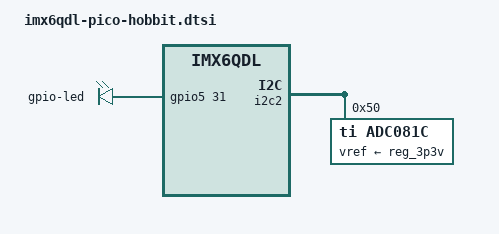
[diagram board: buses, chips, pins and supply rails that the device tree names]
// SPDX-License-Identifier: GPL-2.0+ OR MIT
//
// Copyright 2017 NXP

#include "imx6qdl-pico.dtsi"

/ {
	leds {
		compatible = "gpio-leds";
		pinctrl-names = "default";
		pinctrl-0 = <&pinctrl_gpio_leds>;

		led {
			label = "gpio-led";
			gpios = <&gpio5 31 GPIO_ACTIVE_HIGH>;
		};
	};

};

&i2c2 {
	status = "okay";

	adc081c: adc@50 {
		compatible = "ti,adc081c";
		reg = <0x50>;
		vref-supply = <&reg_3p3v>;
	};
};

&iomuxc {
	pinctrl_gpio_leds: gpioledsgrp {
		fsl,pins = <
			MX6QDL_PAD_CSI0_DAT13__GPIO5_IO31	0x1b0b0
		>;
	};
};
